# BL702 register map
Vendor: Bouffalo Lab; Series: WiFi BT; File version: 1.0
Registers are 32-bit, read-write, reset 0x0 unless marked. A register's access mark holds for its fields unless they carry their own. Offsets are from the block's base; [hi:lo] are bit positions; {n}, {i} and the like mark numbered series.

## UART — Universal Asynchronous Receiver Transmitter
Base 0x4000A000
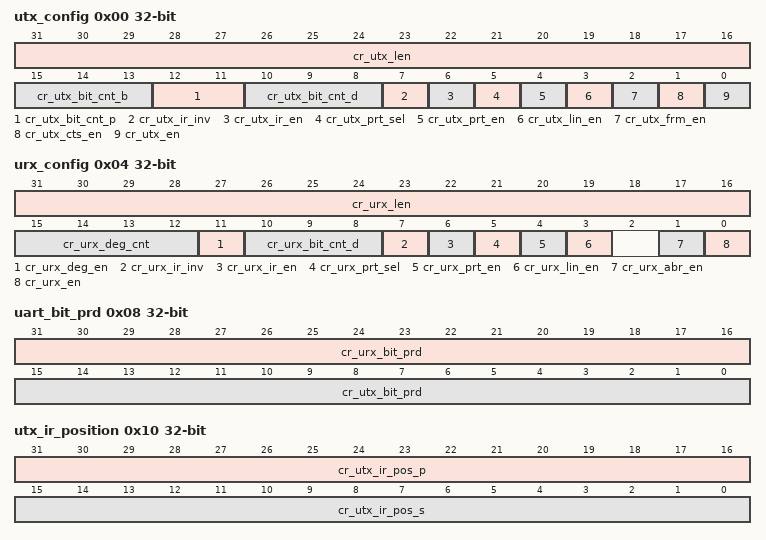
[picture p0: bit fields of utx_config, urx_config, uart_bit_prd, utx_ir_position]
0x00 utx_config
  [31:16] cr_utx_len, [15:13] cr_utx_bit_cnt_b, [12:11] cr_utx_bit_cnt_p, [10:8] cr_utx_bit_cnt_d, [7] cr_utx_ir_inv, [6] cr_utx_ir_en, [5] cr_utx_prt_sel, [4] cr_utx_prt_en, [3] cr_utx_lin_en, [2] cr_utx_frm_en, [1] cr_utx_cts_en, [0] cr_utx_en
0x04 urx_config
  [31:16] cr_urx_len, [15:12] cr_urx_deg_cnt, [11] cr_urx_deg_en, [10:8] cr_urx_bit_cnt_d, [7] cr_urx_ir_inv, [6] cr_urx_ir_en, [5] cr_urx_prt_sel, [4] cr_urx_prt_en, [3] cr_urx_lin_en, [1] cr_urx_abr_en, [0] cr_urx_en
0x08 uart_bit_prd
  [31:16] cr_urx_bit_prd, [15:0] cr_utx_bit_prd
0x0C data_config
  [0] cr_uart_bit_inv
0x10 utx_ir_position
  [31:16] cr_utx_ir_pos_p, [15:0] cr_utx_ir_pos_s
0x14 urx_ir_position
  [15:0] cr_urx_ir_pos_s
0x18 urx_rto_timer
  [7:0] cr_urx_rto_value
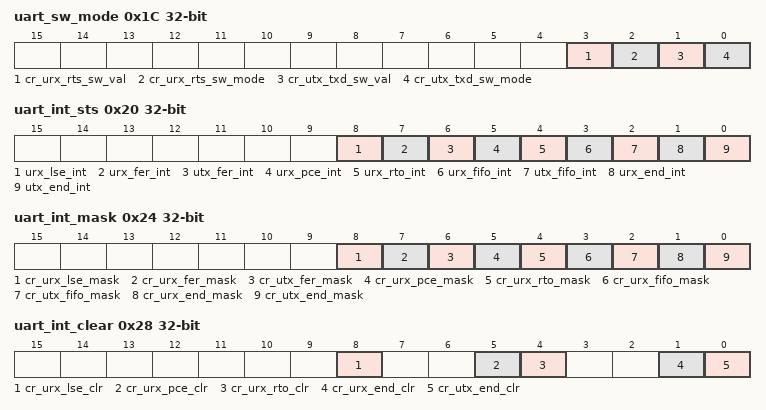
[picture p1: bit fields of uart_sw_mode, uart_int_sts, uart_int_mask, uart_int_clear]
0x1C uart_sw_mode
  [3] cr_urx_rts_sw_val, [2] cr_urx_rts_sw_mode, [1] cr_utx_txd_sw_val, [0] cr_utx_txd_sw_mode
0x20 uart_int_sts — UART interrupt status
  [8] urx_lse_int, [7] urx_fer_int, [6] utx_fer_int, [5] urx_pce_int, [4] urx_rto_int, [3] urx_fifo_int, [2] utx_fifo_int, [1] urx_end_int, [0] utx_end_int
0x24 uart_int_mask — UART interrupt mask
  [8] cr_urx_lse_mask, [7] cr_urx_fer_mask, [6] cr_utx_fer_mask, [5] cr_urx_pce_mask, [4] cr_urx_rto_mask, [3] cr_urx_fifo_mask, [2] cr_utx_fifo_mask, [1] cr_urx_end_mask, [0] cr_utx_end_mask
0x28 uart_int_clear — UART interrupt clear
  [8] cr_urx_lse_clr, [5] cr_urx_pce_clr, [4] cr_urx_rto_clr, [1] cr_urx_end_clr, [0] cr_utx_end_clr
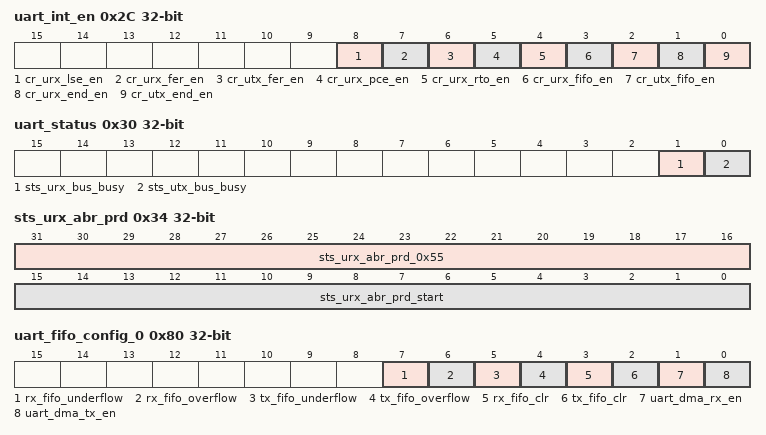
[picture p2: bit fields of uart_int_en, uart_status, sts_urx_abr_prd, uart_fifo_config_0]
0x2C uart_int_en — UART interrupt enable
  [8] cr_urx_lse_en, [7] cr_urx_fer_en, [6] cr_utx_fer_en, [5] cr_urx_pce_en, [4] cr_urx_rto_en, [3] cr_urx_fifo_en, [2] cr_utx_fifo_en, [1] cr_urx_end_en, [0] cr_utx_end_en
0x30 uart_status
  [1] sts_urx_bus_busy, [0] sts_utx_bus_busy
0x34 sts_urx_abr_prd
  [31:16] sts_urx_abr_prd_0x55, [15:0] sts_urx_abr_prd_start
0x80 uart_fifo_config_0
  [7] rx_fifo_underflow, [6] rx_fifo_overflow, [5] tx_fifo_underflow, [4] tx_fifo_overflow, [3] rx_fifo_clr, [2] tx_fifo_clr, [1] uart_dma_rx_en, [0] uart_dma_tx_en
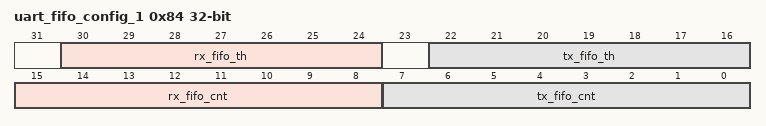
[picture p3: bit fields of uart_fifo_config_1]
0x84 uart_fifo_config_1
  [30:24] rx_fifo_th, [22:16] tx_fifo_th, [15:8] rx_fifo_cnt, [7:0] tx_fifo_cnt
0x88 uart_fifo_wdata
  [7:0] uart_fifo_wdata
0x8C uart_fifo_rdata
  [7:0] uart_fifo_rdata

## SPI — Serial Peripheral Interface
Base 0x4000A200
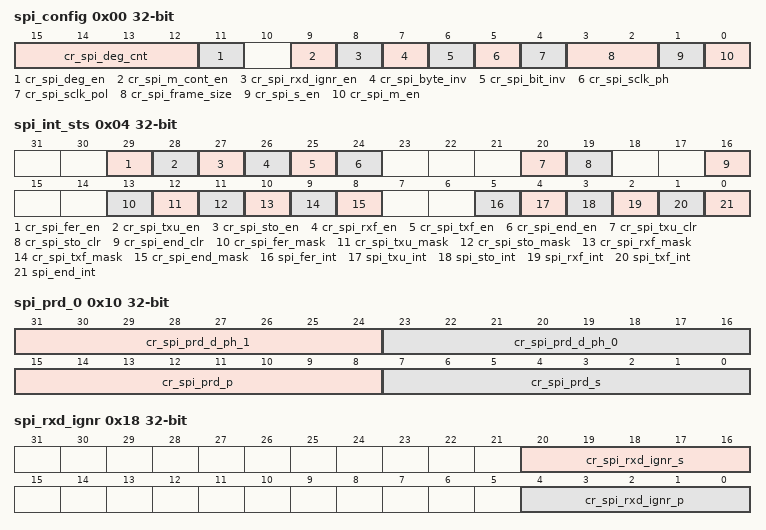
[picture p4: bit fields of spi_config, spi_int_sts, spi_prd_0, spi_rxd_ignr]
0x00 spi_config
  [15:12] cr_spi_deg_cnt, [11] cr_spi_deg_en, [9] cr_spi_m_cont_en, [8] cr_spi_rxd_ignr_en, [7] cr_spi_byte_inv, [6] cr_spi_bit_inv, [5] cr_spi_sclk_ph, [4] cr_spi_sclk_pol, [3:2] cr_spi_frame_size, [1] cr_spi_s_en, [0] cr_spi_m_en
0x04 spi_int_sts
  [29] cr_spi_fer_en, [28] cr_spi_txu_en, [27] cr_spi_sto_en, [26] cr_spi_rxf_en, [25] cr_spi_txf_en, [24] cr_spi_end_en, [20] cr_spi_txu_clr, [19] cr_spi_sto_clr, [16] cr_spi_end_clr, [13] cr_spi_fer_mask, [12] cr_spi_txu_mask, [11] cr_spi_sto_mask, [10] cr_spi_rxf_mask, [9] cr_spi_txf_mask, [8] cr_spi_end_mask, [5] spi_fer_int, [4] spi_txu_int, [3] spi_sto_int, [2] spi_rxf_int, [1] spi_txf_int, [0] spi_end_int
0x08 spi_bus_busy
  [0] sts_spi_bus_busy
0x10 spi_prd_0
  [31:24] cr_spi_prd_d_ph_1, [23:16] cr_spi_prd_d_ph_0, [15:8] cr_spi_prd_p, [7:0] cr_spi_prd_s
0x14 spi_prd_1
  [7:0] cr_spi_prd_i
0x18 spi_rxd_ignr
  [20:16] cr_spi_rxd_ignr_s, [4:0] cr_spi_rxd_ignr_p
0x1C spi_sto_value
  [11:0] cr_spi_sto_value
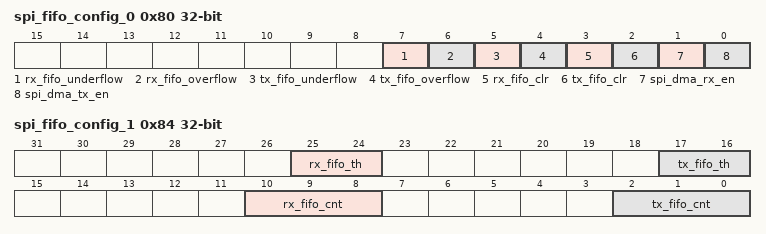
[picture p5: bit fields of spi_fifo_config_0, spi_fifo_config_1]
0x80 spi_fifo_config_0
  [7] rx_fifo_underflow, [6] rx_fifo_overflow, [5] tx_fifo_underflow, [4] tx_fifo_overflow, [3] rx_fifo_clr, [2] tx_fifo_clr, [1] spi_dma_rx_en, [0] spi_dma_tx_en
0x84 spi_fifo_config_1
  [25:24] rx_fifo_th, [17:16] tx_fifo_th, [10:8] rx_fifo_cnt, [2:0] tx_fifo_cnt
0x88 spi_fifo_wdata
0x8C spi_fifo_rdata

## I2C — Inter-Integrated Circuit bus
Base 0x4000A300
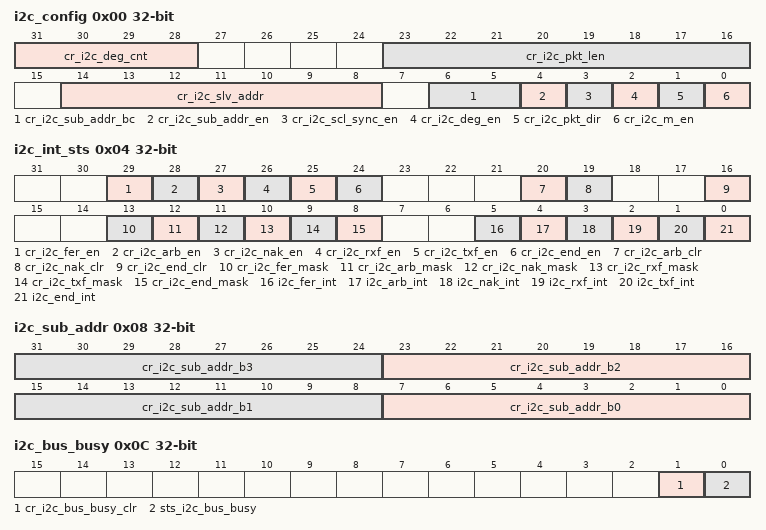
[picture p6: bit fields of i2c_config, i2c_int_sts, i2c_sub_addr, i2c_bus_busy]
0x00 i2c_config
  [31:28] cr_i2c_deg_cnt, [23:16] cr_i2c_pkt_len, [14:8] cr_i2c_slv_addr, [6:5] cr_i2c_sub_addr_bc, [4] cr_i2c_sub_addr_en, [3] cr_i2c_scl_sync_en, [2] cr_i2c_deg_en, [1] cr_i2c_pkt_dir, [0] cr_i2c_m_en
0x04 i2c_int_sts
  [29] cr_i2c_fer_en, [28] cr_i2c_arb_en, [27] cr_i2c_nak_en, [26] cr_i2c_rxf_en, [25] cr_i2c_txf_en, [24] cr_i2c_end_en, [20] cr_i2c_arb_clr, [19] cr_i2c_nak_clr, [16] cr_i2c_end_clr, [13] cr_i2c_fer_mask, [12] cr_i2c_arb_mask, [11] cr_i2c_nak_mask, [10] cr_i2c_rxf_mask, [9] cr_i2c_txf_mask, [8] cr_i2c_end_mask, [5] i2c_fer_int, [4] i2c_arb_int, [3] i2c_nak_int, [2] i2c_rxf_int, [1] i2c_txf_int, [0] i2c_end_int
0x08 i2c_sub_addr
  [8n+7:8n] cr_i2c_sub_addr_b{n} (n=0..3)
0x0C i2c_bus_busy
  [1] cr_i2c_bus_busy_clr, [0] sts_i2c_bus_busy
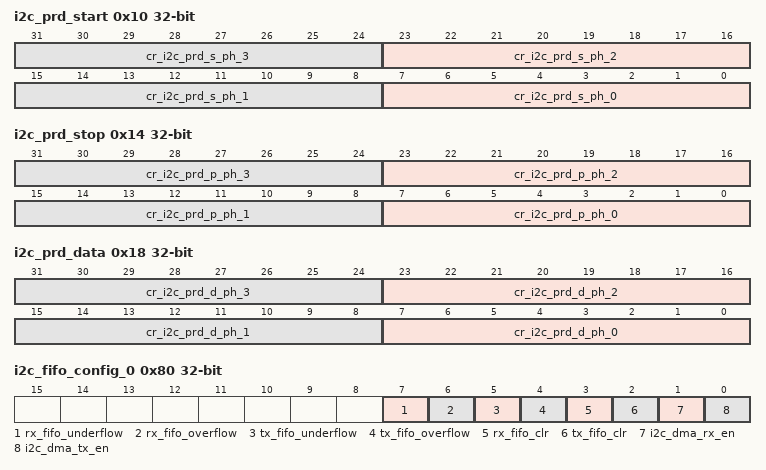
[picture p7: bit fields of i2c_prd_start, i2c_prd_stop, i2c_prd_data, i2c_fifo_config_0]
0x10 i2c_prd_start
  [8n+7:8n] cr_i2c_prd_s_ph_{n} (n=0..3)
0x14 i2c_prd_stop
  [8n+7:8n] cr_i2c_prd_p_ph_{n} (n=0..3)
0x18 i2c_prd_data
  [8n+7:8n] cr_i2c_prd_d_ph_{n} (n=0..3)
0x80 i2c_fifo_config_0
  [7] rx_fifo_underflow, [6] rx_fifo_overflow, [5] tx_fifo_underflow, [4] tx_fifo_overflow, [3] rx_fifo_clr, [2] tx_fifo_clr, [1] i2c_dma_rx_en, [0] i2c_dma_tx_en
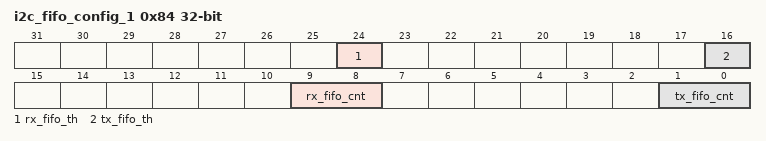
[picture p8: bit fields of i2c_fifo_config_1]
0x84 i2c_fifo_config_1
  [24] rx_fifo_th, [16] tx_fifo_th, [9:8] rx_fifo_cnt, [1:0] tx_fifo_cnt
0x88 i2c_fifo_wdata
0x8C i2c_fifo_rdata
